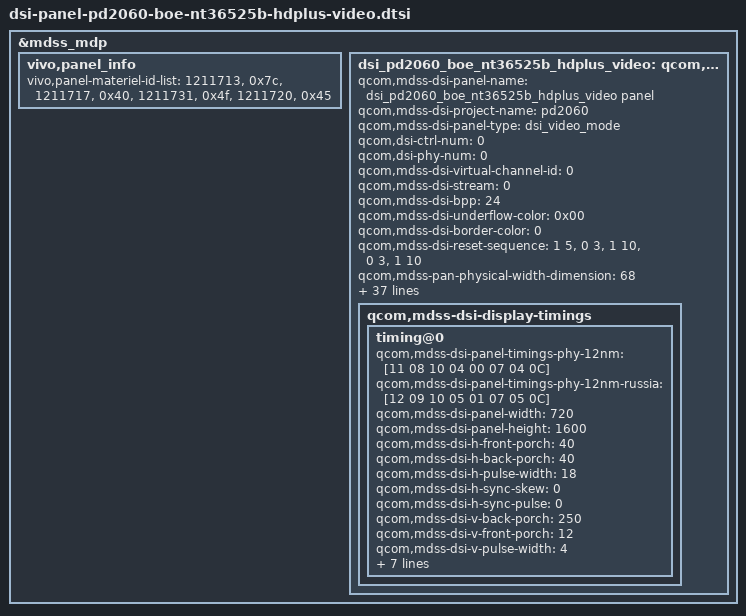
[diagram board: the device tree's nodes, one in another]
/* Copyright (c) 2019, The Linux Foundation. All rights reserved.
 *
 * This program is free software; you can redistribute it and/or modify
 * it under the terms of the GNU General Public License version 2 and
 * only version 2 as published by the Free Software Foundation.
 *
 * This program is distributed in the hope that it will be useful,
 * but WITHOUT ANY WARRANTY; without even the implied warranty of
 * MERCHANTABILITY or FITNESS FOR A PARTICULAR PURPOSE.  See the
 * GNU General Public License for more details.
 */

&mdss_mdp {

	/* vivo panel materiel info start */
	/* No add new id until you have import driver for new panel ok!!!!!! */
	vivo,panel_info {
		/* vivo,panel-materiel-id-list = "materiel_id1", "lcm1_sf_id1 lcm1_sf_id2 lcm1_sf_id3...",
					"materiel_id2", "lcm2_sf_id1 lcm2_sf_id2 lcm2_sf_id3...",
					...
					"materiel_idX, "lcmX_sf_id1, lcmX_sf_id2, lcmX_sf_id3...";
		*/
		vivo,panel-materiel-id-list = "1211713", "0x7c",
					"1211717", "0x40",
					"1211731", "0x4f",
					"1211720", "0x45";
	};
	/* vivo panel materiel info end */

	dsi_pd2060_boe_nt36525b_hdplus_video: qcom,mdss_dsi_pd2060_boe_nt36525b_hdplus_video {
		qcom,mdss-dsi-panel-name = "dsi_pd2060_boe_nt36525b_hdplus_video panel";
		qcom,mdss-dsi-project-name = "pd2060";
		qcom,mdss-dsi-panel-type = "dsi_video_mode";

		qcom,dsi-ctrl-num = <0>;
		qcom,dsi-phy-num = <0>;

		qcom,mdss-dsi-virtual-channel-id = <0>;
		qcom,mdss-dsi-stream = <0>;
		qcom,mdss-dsi-bpp = <24>;
		qcom,mdss-dsi-underflow-color = <0x00>;
		qcom,mdss-dsi-border-color = <0>;
		qcom,mdss-dsi-reset-sequence =<1 5>, <0 3>, <1 10>, <0 3>, <1 10>;
		qcom,mdss-pan-physical-width-dimension = <68>;
		qcom,mdss-pan-physical-height-dimension = <151>;
		qcom,mdss-dsi-traffic-mode = "non_burst_sync_event";
		qcom,mdss-dsi-bllp-eof-power-mode;
		qcom,mdss-dsi-bllp-power-mode;
		qcom,mdss-dsi-lane-0-state;
		qcom,mdss-dsi-lane-1-state;
		qcom,mdss-dsi-lane-2-state;
		qcom,mdss-dsi-dma-trigger = "trigger_sw";
		qcom,mdss-dsi-mdp-trigger = "none";
		qcom,mdss-dsi-panel-id = <0x31>;
		qcom,mdss-dsi-lcmid-sequence = <0x31 0x7C>;
		qcom,mdss-dsi-backlight-hw-id-offset = <7>;
		qcom,mdss-dsi-lp11-init;
		qcom,vivo-dsi-panel-type = "tft";
		qcom,mdss-dsi-panel-physical-type = "lcd";
		qcom,mdss-panel-sre;
		qcom,mdss-dsi-lcm-sre-max-level = <0x08>;
		qcom,bl-update-flag = "delay_until_first_frame";
		qcom,esd-check-more;
		qcom,mdss-dsi-on-cabc-levle1 = [
			39 01 00 00 00 00 02 53 2C
			39 01 00 00 00 00 02 55 01
		];

		qcom,mdss-dsi-on-cabc-levle2 = [
			39 01 00 00 00 00 02 53 2C
			39 01 00 00 00 00 02 55 02
		];

		qcom,mdss-dsi-on-cabc-levle3 = [
			39 01 00 00 00 00 02 53 2C
			39 01 00 00 00 00 02 55 03
		];

		qcom,mdss-dsi-on-cabc-off = [
			39 01 00 00 00 00 02 53 2C
			39 01 00 00 00 00 02 55 00
		];

		qcom,mdss-dsi-off-command = [
			05 01 00 00 11 00 01 28
			05 01 00 00 50 00 01 10
		];

		qcom,mdss-dsi-pre-off-command = [
			05 01 00 00 11 00 01 28
		];
		qcom,mdss-dsi-pre-on-command = [
			39 01 00 00 14 00 01 29
		];

		qcom,mdss-dsi-on-command-state = "dsi_lp_mode";
		qcom,mdss-dsi-off-command-state = "dsi_hs_mode";
		qcom,mdss-alpm-command-state = "dsi_hs_mode";

		qcom,mdss-dsi-display-timings {
			timing@0{
				qcom,mdss-dsi-panel-timings-phy-12nm = [11 08 10 04 00 07 04 0C];
				qcom,mdss-dsi-panel-timings-phy-12nm-russia = [12 09 10 05 01 07 05 0C];
				qcom,mdss-dsi-panel-width = <720>;
				qcom,mdss-dsi-panel-height = <1600>;
				qcom,mdss-dsi-h-front-porch = <40>;
				qcom,mdss-dsi-h-back-porch = <40>;
				qcom,mdss-dsi-h-pulse-width = <18>;
				qcom,mdss-dsi-h-sync-skew = <0>;
				qcom,mdss-dsi-h-sync-pulse = <0>;
				qcom,mdss-dsi-v-back-porch = <250>;
				qcom,mdss-dsi-v-front-porch = <12>;
				qcom,mdss-dsi-v-pulse-width = <4>;
				qcom,mdss-dsi-panel-framerate = <60>;
				qcom,mdss-dsi-h-left-border = <0>;
				qcom,mdss-dsi-h-right-border = <0>;
				qcom,mdss-dsi-v-top-border = <0>;
				qcom,mdss-dsi-v-bottom-border = <0>;
				qcom,mdss-dsi-on-command =
				[
					/* Gamma setting */
					 39 01 00 00 00 00 02 FF 20
					 39 01 00 00 00 00 02 FB 01
					 39 01 00 00 00 00 11 B0 00 6E 00 7B 00 86 00 93 00 A0 00 AC 00 B6 00 C3
					 39 01 00 00 00 00 11 B1 00 CD 00 F0 01 11 01 48 01 74 01 BE 01 FC 01 FE
					 39 01 00 00 00 00 11 B2 02 3A 02 7F 02 AC 02 E7 03 0E 03 3C 03 4A 03 59
					 39 01 00 00 00 00 0D B3 03 6C 03 82 03 9E 03 BE 03 D9 03 DA
					 39 01 00 00 00 00 11 B4 00 38 00 45 00 59 00 6B 00 7A 00 88 00 94 00 A2
					 39 01 00 00 00 00 11 B5 00 AE 00 DA 00 FE 01 3B 01 6B 01 B9 01 F7 01 F9
					 39 01 00 00 00 00 11 B6 02 36 02 7C 02 A9 02 E4 03 09 03 38 03 47 03 56
					 39 01 00 00 00 00 0D B7 03 69 03 7E 03 9A 03 B7 03 D9 03 DA
					 39 01 00 00 00 00 11 B8 00 00 00 0E 00 2B 00 41 00 53 00 65 00 74 00 83
					 39 01 00 00 00 00 11 B9 00 93 00 C5 00 EE 01 31 01 65 01 B6 01 F5 01 F7
					 39 01 00 00 00 00 11 BA 02 34 02 7B 02 A9 02 E6 03 0E 03 40 03 49 03 59
					 39 01 00 00 00 00 0D BB 03 65 03 78 03 92 03 B5 03 D8 03 DA
					 39 01 00 00 00 00 02 FF 21
					 39 01 00 00 00 00 02 FB 01
					 39 01 00 00 00 00 11 B0 00 6E 00 73 00 7E 00 8B 00 98 00 A4 00 AE 00 BB
					 39 01 00 00 00 00 11 B1 00 C5 00 E8 01 09 01 40 01 6C 01 B6 01 F4 01 F6
					 39 01 00 00 00 00 11 B2 02 32 02 77 02 A4 02 DF 03 06 03 34 03 42 03 51
					 39 01 00 00 00 00 0D B3 03 64 03 7A 03 96 03 B6 03 D1 03 DA
					 39 01 00 00 00 00 11 B4 00 38 00 3D 00 51 00 63 00 72 00 80 00 8E 00 9A
					 39 01 00 00 00 00 11 B5 00 A6 00 D2 00 F6 01 33 01 63 01 B2 01 EF 01 F1
					 39 01 00 00 00 00 11 B6 02 2E 02 74 02 A1 02 DC 03 01 03 30 03 3F 03 4E
					 39 01 00 00 00 00 0D B7 03 61 03 76 03 92 03 AF 03 D1 03 DA
					 39 01 00 00 00 00 11 B8 00 00 00 06 00 23 00 39 00 4B 00 5D 00 6C 00 7B
					 39 01 00 00 00 00 11 B9 00 8B 00 BD 00 E6 01 29 01 5D 01 AE 01 ED 01 EF
					 39 01 00 00 00 00 11 BA 02 2C 02 73 02 A1 02 DE 03 06 03 3A 03 41 03 51
					 39 01 00 00 00 00 0D BB 03 5D 03 70 03 8A 03 AD 03 D0 03 DA

                     /*LV detect debounce time*/
					 39 01 00 00 01 00 02 FF F0
					 39 01 00 00 00 00 02 FB 01
					 39 01 00 00 00 00 02 CF 22

					 /*sre setting*/
					 39 01 00 00 00 00 02 FF 22
					 39 01 00 00 00 00 02 FB 01
					 39 01 00 00 00 00 02 1A 00
					 39 01 00 00 00 00 02 53 00
					 39 01 00 00 00 00 02 68 00
					 39 01 00 00 00 00 02 56 77
					 39 01 00 00 00 00 02 58 10
					 39 01 00 00 00 00 02 59 10
					 39 01 00 00 00 00 02 5E 10
					 39 01 00 00 00 00 02 5F 10
					 39 01 00 00 00 00 02 6A 00

                     /*cabc ui mode setting*/
					 39 01 00 00 00 00 02 FF 23
					 39 01 00 00 00 00 02 FB 01
					 39 01 00 00 00 00 02 30 FF
					 39 01 00 00 00 00 02 31 FE
					 39 01 00 00 00 00 02 32 EB
					 39 01 00 00 00 00 02 33 E5
					 39 01 00 00 00 00 02 34 DD
					 39 01 00 00 00 00 02 35 DA
					 39 01 00 00 00 00 02 36 D5
					 39 01 00 00 00 00 02 37 D0
					 39 01 00 00 00 00 02 38 CE
					 39 01 00 00 00 00 02 39 CD
					 39 01 00 00 00 00 02 3A CD
					 39 01 00 00 00 00 02 3B CD
					 39 01 00 00 00 00 02 3D CB
					 39 01 00 00 00 00 02 3F CB
					 39 01 00 00 00 00 02 40 C6
					 39 01 00 00 00 00 02 41 BF
					 /*still mode*/
					 39 01 00 00 00 00 02 45 FF
					 39 01 00 00 00 00 02 46 F0
					 39 01 00 00 00 00 02 47 E8
					 39 01 00 00 00 00 02 48 CE
					 39 01 00 00 00 00 02 49 BC
					 39 01 00 00 00 00 02 4A B8
					 39 01 00 00 00 00 02 4B B5
					 39 01 00 00 00 00 02 4C B0
					 39 01 00 00 00 00 02 4D A8
					 39 01 00 00 00 00 02 4E A0
					 39 01 00 00 00 00 02 4F 9B
					 39 01 00 00 00 00 02 50 98
					 39 01 00 00 00 00 02 51 98
					 39 01 00 00 00 00 02 52 88
					 39 01 00 00 00 00 02 53 80
					 39 01 00 00 00 00 02 54 7F
					 /*dimming setting*/
					 39 01 00 00 00 00 02 04 05
					 39 01 00 00 00 00 02 05 2D
					 39 01 00 00 00 00 02 06 01
					 /* 12bit brightness resolution */
					 39 01 00 00 00 00 02 00 80
					 /* set pwm frequency to 15KHz, 12bit bklt has different rule to calc freq with 8bit bklt*/
					 39 01 00 00 00 00 02 07 00
					 39 01 00 00 00 00 02 08 01
					 /*osc -1% && vfp=12*/
					 39 01 00 00 01 00 02 FF 25
					 39 01 00 00 00 00 02 FB 01
					 39 01 00 00 00 00 02 0A 82
					 39 01 00 00 00 00 02 0B 1F
					 39 01 00 00 00 00 02 0C 01

					 39 01 00 00 01 00 02 FF 24
					 39 01 00 00 00 00 02 FB 01
					 39 01 00 00 00 00 02 92 B1
					 39 01 00 00 00 00 02 B1 AD
					 39 01 00 00 00 00 02 93 0C
					 39 01 00 00 00 00 02 94 0C
					 /* Sharpness setting */
					 39 01 00 00 00 00 02 FF 10
					 39 01 00 00 00 00 02 FB 01
					 39 01 00 00 00 00 02 55 80
					 39 01 00 00 00 00 02 FF 22
					 39 01 00 00 00 00 02 FB 01
					 39 01 00 00 00 00 02 1A 00
					 39 01 00 00 00 00 02 53 00
					 39 01 00 00 00 00 02 56 77
					 39 01 00 00 00 00 02 68 01
					 39 01 00 00 00 00 02 65 80
					 39 01 00 00 00 00 02 66 80
					 39 01 00 00 00 00 02 67 80
					 /*Backlight setting*/
					 39 01 00 00 00 00 02 FF 10
					 39 01 00 00 00 00 02 FB 01
					 39 01 00 00 00 00 02 35 00
					 39 01 00 00 00 00 03 51 00 00
					 39 01 00 00 00 00 03 68 03 01
					 39 01 00 00 00 00 02 53 24
					 /*02-3lane 03-4lane*/
					 39 01 00 00 00 00 02 BA 02
					 /*sleep out & display on*/
					 39 01 00 00 14 00 01 29
					 39 01 00 00 64 00 01 11
				];
			};
		};
	};
};

